# CONTROL_MODULE register map
Vendor: Texas Instruments
Registers are 32-bit, access per field, no defined reset value unless marked. A register's access mark holds for its fields unless they carry their own. Offsets are as the file gives them; [hi:lo] are bit positions.

## CONTROL_MODULE (part 3 of 5)
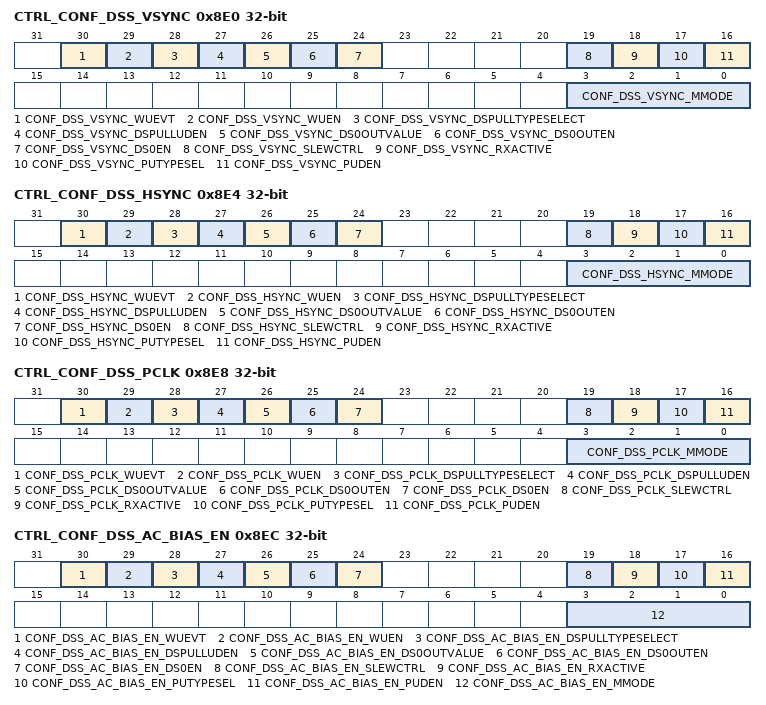
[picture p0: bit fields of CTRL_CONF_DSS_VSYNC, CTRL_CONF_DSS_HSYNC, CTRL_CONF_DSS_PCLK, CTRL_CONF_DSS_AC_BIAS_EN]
0x8E0 CTRL_CONF_DSS_VSYNC
  [30] CONF_DSS_VSYNC_WUEVT ro — Wakeup Event [[br]]0 = No event [[br]]1 = Event occurred
  [29] CONF_DSS_VSYNC_WUEN rw — Wakeup enable [[br]]0 = disable [[br]]1 = enable
  [28] CONF_DSS_VSYNC_DSPULLTYPESELECT rw — DS0 mode Pull-Up/Down selection [[br]]0 = Offmode Pull-Down selected [[br]]1 = Offmode Pull-Up selected
  [27] CONF_DSS_VSYNC_DSPULLUDEN rw — DS0 mode Pull-Up/Down enable. [[br]]This is an active low signal. [[br]]1 = Pullup / Pulldown disabled [[br]]0 = Pullup / Pulldown enabled
  [26] CONF_DSS_VSYNC_DS0OUTVALUE rw — DS0 mode output value [[br]]0 = Set value at 0 [[br]]1 = Set value at 1
  [25] CONF_DSS_VSYNC_DS0OUTEN rw — DS0 mode output enable This is an active low signal [[br]]0 = Output Enable [[br]]1 = Output Disable
  [24] CONF_DSS_VSYNC_DS0EN rw — DS0 mode override control [[br]]0: IO state keeps its previous state when DS0 mode is active [[br]]1: IO state is forced to OFF mode value when DS0 mode is active
  [19] CONF_DSS_VSYNC_SLEWCTRL rw — Select between Faster or Slower Slew rate [[br]]0 = fast [[br]]1 = slow
  [18] CONF_DSS_VSYNC_RXACTIVE rw — Input Enable Value for the PAD [[br]]0 = receiver disabled [[br]]1 = receiver enabled
  [17] CONF_DSS_VSYNC_PUTYPESEL rw — Pad Pullup / Pulldown Type Selection [[br]]0 = Pulldown selected [[br]]1 = Pullup selected
  [16] CONF_DSS_VSYNC_PUDEN rw — Pad Pullup / Pulldown Enable. [[br]]This is an active low signal [[br]]1 = Pullup / Pulldown disabled [[br]]0 = Pullup / Pulldown enabled
  [3:0] CONF_DSS_VSYNC_MMODE rw — Pad Functional Signal Mux Select
0x8E4 CTRL_CONF_DSS_HSYNC
  [30] CONF_DSS_HSYNC_WUEVT ro — Wakeup Event [[br]]0 = No event [[br]]1 = Event occurred
  [29] CONF_DSS_HSYNC_WUEN rw — Wakeup enable [[br]]0 = disable [[br]]1 = enable
  [28] CONF_DSS_HSYNC_DSPULLTYPESELECT rw — DS0 mode Pull-Up/Down selection [[br]]0 = Offmode Pull-Down selected [[br]]1 = Offmode Pull-Up selected
  [27] CONF_DSS_HSYNC_DSPULLUDEN rw — DS0 mode Pull-Up/Down enable. [[br]]This is an active low signal. [[br]]1 = Pullup / Pulldown disabled [[br]]0 = Pullup / Pulldown enabled
  [26] CONF_DSS_HSYNC_DS0OUTVALUE rw — DS0 mode output value [[br]]0 = Set value at 0 [[br]]1 = Set value at 1
  [25] CONF_DSS_HSYNC_DS0OUTEN rw — DS0 mode output enable This is an active low signal [[br]]0 = Output Enable [[br]]1 = Output Disable
  [24] CONF_DSS_HSYNC_DS0EN rw — DS0 mode override control [[br]]0: IO state keeps its previous state when DS0 mode is active [[br]]1: IO state is forced to OFF mode value when DS0 mode is active
  [19] CONF_DSS_HSYNC_SLEWCTRL rw — Select between Faster or Slower Slew rate [[br]]0 = fast [[br]]1 = slow
  [18] CONF_DSS_HSYNC_RXACTIVE rw — Input Enable Value for the PAD [[br]]0 = receiver disabled [[br]]1 = receiver enabled
  [17] CONF_DSS_HSYNC_PUTYPESEL rw — Pad Pullup / Pulldown Type Selection [[br]]0 = Pulldown selected [[br]]1 = Pullup selected
  [16] CONF_DSS_HSYNC_PUDEN rw — Pad Pullup / Pulldown Enable. [[br]]This is an active low signal [[br]]1 = Pullup / Pulldown disabled [[br]]0 = Pullup / Pulldown enabled
  [3:0] CONF_DSS_HSYNC_MMODE rw — Pad Functional Signal Mux Select
0x8E8 CTRL_CONF_DSS_PCLK
  [30] CONF_DSS_PCLK_WUEVT ro — Wakeup Event [[br]]0 = No event [[br]]1 = Event occurred
  [29] CONF_DSS_PCLK_WUEN rw — Wakeup enable [[br]]0 = disable [[br]]1 = enable
  [28] CONF_DSS_PCLK_DSPULLTYPESELECT rw — DS0 mode Pull-Up/Down selection [[br]]0 = Offmode Pull-Down selected [[br]]1 = Offmode Pull-Up selected
  [27] CONF_DSS_PCLK_DSPULLUDEN rw — DS0 mode Pull-Up/Down enable. [[br]]This is an active low signal. [[br]]1 = Pullup / Pulldown disabled [[br]]0 = Pullup / Pulldown enabled
  [26] CONF_DSS_PCLK_DS0OUTVALUE rw — DS0 mode output value [[br]]0 = Set value at 0 [[br]]1 = Set value at 1
  [25] CONF_DSS_PCLK_DS0OUTEN rw — DS0 mode output enable This is an active low signal [[br]]0 = Output Enable [[br]]1 = Output Disable
  [24] CONF_DSS_PCLK_DS0EN rw — DS0 mode override control [[br]]0: IO state keeps its previous state when DS0 mode is active [[br]]1: IO state is forced to OFF mode value when DS0 mode is active
  [19] CONF_DSS_PCLK_SLEWCTRL rw — Select between Faster or Slower Slew rate [[br]]0 = fast [[br]]1 = slow
  [18] CONF_DSS_PCLK_RXACTIVE rw — Input Enable Value for the PAD [[br]]0 = receiver disabled [[br]]1 = receiver enabled
  [17] CONF_DSS_PCLK_PUTYPESEL rw — Pad Pullup / Pulldown Type Selection [[br]]0 = Pulldown selected [[br]]1 = Pullup selected
  [16] CONF_DSS_PCLK_PUDEN rw — Pad Pullup / Pulldown Enable. [[br]]This is an active low signal [[br]]1 = Pullup / Pulldown disabled [[br]]0 = Pullup / Pulldown enabled
  [3:0] CONF_DSS_PCLK_MMODE rw — Pad Functional Signal Mux Select
0x8EC CTRL_CONF_DSS_AC_BIAS_EN
  [30] CONF_DSS_AC_BIAS_EN_WUEVT ro — Wakeup Event [[br]]0 = No event [[br]]1 = Event occurred
  [29] CONF_DSS_AC_BIAS_EN_WUEN rw — Wakeup enable [[br]]0 = disable [[br]]1 = enable
  [28] CONF_DSS_AC_BIAS_EN_DSPULLTYPESELECT rw — DS0 mode Pull-Up/Down selection [[br]]0 = Offmode Pull-Down selected [[br]]1 = Offmode Pull-Up selected
  [27] CONF_DSS_AC_BIAS_EN_DSPULLUDEN rw — DS0 mode Pull-Up/Down enable. [[br]]This is an active low signal. [[br]]1 = Pullup / Pulldown disabled [[br]]0 = Pullup / Pulldown enabled
  [26] CONF_DSS_AC_BIAS_EN_DS0OUTVALUE rw — DS0 mode output value [[br]]0 = Set value at 0 [[br]]1 = Set value at 1
  [25] CONF_DSS_AC_BIAS_EN_DS0OUTEN rw — DS0 mode output enable This is an active low signal [[br]]0 = Output Enable [[br]]1 = Output Disable
  [24] CONF_DSS_AC_BIAS_EN_DS0EN rw — DS0 mode override control [[br]]0: IO state keeps its previous state when DS0 mode is active [[br]]1: IO state is forced to OFF mode value when DS0 mode is active
  [19] CONF_DSS_AC_BIAS_EN_SLEWCTRL rw — Select between Faster or Slower Slew rate [[br]]0 = fast [[br]]1 = slow
  [18] CONF_DSS_AC_BIAS_EN_RXACTIVE rw — Input Enable Value for the PAD [[br]]0 = receiver disabled [[br]]1 = receiver enabled
  [17] CONF_DSS_AC_BIAS_EN_PUTYPESEL rw — Pad Pullup / Pulldown Type Selection [[br]]0 = Pulldown selected [[br]]1 = Pullup selected
  [16] CONF_DSS_AC_BIAS_EN_PUDEN rw — Pad Pullup / Pulldown Enable. [[br]]This is an active low signal [[br]]1 = Pullup / Pulldown disabled [[br]]0 = Pullup / Pulldown enabled
  [3:0] CONF_DSS_AC_BIAS_EN_MMODE rw — Pad Functional Signal Mux Select
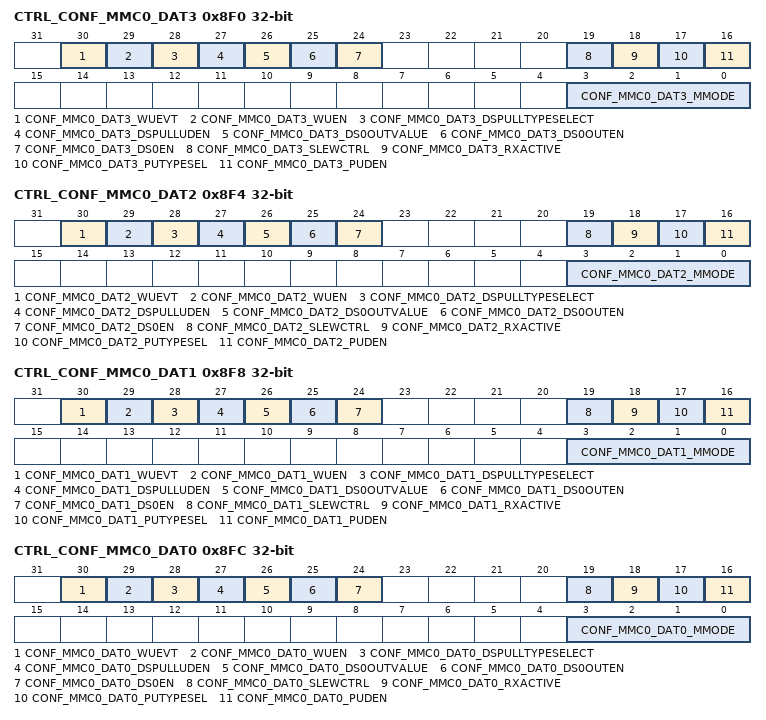
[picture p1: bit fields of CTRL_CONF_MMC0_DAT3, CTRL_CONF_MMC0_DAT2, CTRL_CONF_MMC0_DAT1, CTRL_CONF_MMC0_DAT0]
0x8F0 CTRL_CONF_MMC0_DAT3
  [30] CONF_MMC0_DAT3_WUEVT ro — Wakeup Event [[br]]0 = No event [[br]]1 = Event occurred
  [29] CONF_MMC0_DAT3_WUEN rw — Wakeup enable [[br]]0 = disable [[br]]1 = enable
  [28] CONF_MMC0_DAT3_DSPULLTYPESELECT rw — DS0 mode Pull-Up/Down selection [[br]]0 = Offmode Pull-Down selected [[br]]1 = Offmode Pull-Up selected
  [27] CONF_MMC0_DAT3_DSPULLUDEN rw — DS0 mode Pull-Up/Down enable. [[br]]This is an active low signal. [[br]]1 = Pullup / Pulldown disabled [[br]]0 = Pullup / Pulldown enabled
  [26] CONF_MMC0_DAT3_DS0OUTVALUE rw — DS0 mode output value [[br]]0 = Set value at 0 [[br]]1 = Set value at 1
  [25] CONF_MMC0_DAT3_DS0OUTEN rw — DS0 mode output enable This is an active low signal [[br]]0 = Output Enable [[br]]1 = Output Disable
  [24] CONF_MMC0_DAT3_DS0EN rw — DS0 mode override control [[br]]0: IO state keeps its previous state when DS0 mode is active [[br]]1: IO state is forced to OFF mode value when DS0 mode is active
  [19] CONF_MMC0_DAT3_SLEWCTRL rw — Select between Faster or Slower Slew rate [[br]]0 = fast [[br]]1 = slow
  [18] CONF_MMC0_DAT3_RXACTIVE rw — Input Enable Value for the PAD [[br]]0 = receiver disabled [[br]]1 = receiver enabled
  [17] CONF_MMC0_DAT3_PUTYPESEL rw — Pad Pullup / Pulldown Type Selection [[br]]0 = Pulldown selected [[br]]1 = Pullup selected
  [16] CONF_MMC0_DAT3_PUDEN rw — Pad Pullup / Pulldown Enable. [[br]]This is an active low signal [[br]]1 = Pullup / Pulldown disabled [[br]]0 = Pullup / Pulldown enabled
  [3:0] CONF_MMC0_DAT3_MMODE rw — Pad Functional Signal Mux Select
0x8F4 CTRL_CONF_MMC0_DAT2
  [30] CONF_MMC0_DAT2_WUEVT ro — Wakeup Event [[br]]0 = No event [[br]]1 = Event occurred
  [29] CONF_MMC0_DAT2_WUEN rw — Wakeup enable [[br]]0 = disable [[br]]1 = enable
  [28] CONF_MMC0_DAT2_DSPULLTYPESELECT rw — DS0 mode Pull-Up/Down selection [[br]]0 = Offmode Pull-Down selected [[br]]1 = Offmode Pull-Up selected
  [27] CONF_MMC0_DAT2_DSPULLUDEN rw — DS0 mode Pull-Up/Down enable. [[br]]This is an active low signal. [[br]]1 = Pullup / Pulldown disabled [[br]]0 = Pullup / Pulldown enabled
  [26] CONF_MMC0_DAT2_DS0OUTVALUE rw — DS0 mode output value [[br]]0 = Set value at 0 [[br]]1 = Set value at 1
  [25] CONF_MMC0_DAT2_DS0OUTEN rw — DS0 mode output enable This is an active low signal [[br]]0 = Output Enable [[br]]1 = Output Disable
  [24] CONF_MMC0_DAT2_DS0EN rw — DS0 mode override control [[br]]0: IO state keeps its previous state when DS0 mode is active [[br]]1: IO state is forced to OFF mode value when DS0 mode is active
  [19] CONF_MMC0_DAT2_SLEWCTRL rw — Select between Faster or Slower Slew rate [[br]]0 = fast [[br]]1 = slow
  [18] CONF_MMC0_DAT2_RXACTIVE rw — Input Enable Value for the PAD [[br]]0 = receiver disabled [[br]]1 = receiver enabled
  [17] CONF_MMC0_DAT2_PUTYPESEL rw — Pad Pullup / Pulldown Type Selection [[br]]0 = Pulldown selected [[br]]1 = Pullup selected
  [16] CONF_MMC0_DAT2_PUDEN rw — Pad Pullup / Pulldown Enable. [[br]]This is an active low signal [[br]]1 = Pullup / Pulldown disabled [[br]]0 = Pullup / Pulldown enabled
  [3:0] CONF_MMC0_DAT2_MMODE rw — Pad Functional Signal Mux Select
0x8F8 CTRL_CONF_MMC0_DAT1
  [30] CONF_MMC0_DAT1_WUEVT ro — Wakeup Event [[br]]0 = No event [[br]]1 = Event occurred
  [29] CONF_MMC0_DAT1_WUEN rw — Wakeup enable [[br]]0 = disable [[br]]1 = enable
  [28] CONF_MMC0_DAT1_DSPULLTYPESELECT rw — DS0 mode Pull-Up/Down selection [[br]]0 = Offmode Pull-Down selected [[br]]1 = Offmode Pull-Up selected
  [27] CONF_MMC0_DAT1_DSPULLUDEN rw — DS0 mode Pull-Up/Down enable. [[br]]This is an active low signal. [[br]]1 = Pullup / Pulldown disabled [[br]]0 = Pullup / Pulldown enabled
  [26] CONF_MMC0_DAT1_DS0OUTVALUE rw — DS0 mode output value [[br]]0 = Set value at 0 [[br]]1 = Set value at 1
  [25] CONF_MMC0_DAT1_DS0OUTEN rw — DS0 mode output enable This is an active low signal [[br]]0 = Output Enable [[br]]1 = Output Disable
  [24] CONF_MMC0_DAT1_DS0EN rw — DS0 mode override control [[br]]0: IO state keeps its previous state when DS0 mode is active [[br]]1: IO state is forced to OFF mode value when DS0 mode is active
  [19] CONF_MMC0_DAT1_SLEWCTRL rw — Select between Faster or Slower Slew rate [[br]]0 = fast [[br]]1 = slow
  [18] CONF_MMC0_DAT1_RXACTIVE rw — Input Enable Value for the PAD [[br]]0 = receiver disabled [[br]]1 = receiver enabled
  [17] CONF_MMC0_DAT1_PUTYPESEL rw — Pad Pullup / Pulldown Type Selection [[br]]0 = Pulldown selected [[br]]1 = Pullup selected
  [16] CONF_MMC0_DAT1_PUDEN rw — Pad Pullup / Pulldown Enable. [[br]]This is an active low signal [[br]]1 = Pullup / Pulldown disabled [[br]]0 = Pullup / Pulldown enabled
  [3:0] CONF_MMC0_DAT1_MMODE rw — Pad Functional Signal Mux Select
0x8FC CTRL_CONF_MMC0_DAT0
  [30] CONF_MMC0_DAT0_WUEVT ro — Wakeup Event [[br]]0 = No event [[br]]1 = Event occurred
  [29] CONF_MMC0_DAT0_WUEN rw — Wakeup enable [[br]]0 = disable [[br]]1 = enable
  [28] CONF_MMC0_DAT0_DSPULLTYPESELECT rw — DS0 mode Pull-Up/Down selection [[br]]0 = Offmode Pull-Down selected [[br]]1 = Offmode Pull-Up selected
  [27] CONF_MMC0_DAT0_DSPULLUDEN rw — DS0 mode Pull-Up/Down enable. [[br]]This is an active low signal. [[br]]1 = Pullup / Pulldown disabled [[br]]0 = Pullup / Pulldown enabled
  [26] CONF_MMC0_DAT0_DS0OUTVALUE rw — DS0 mode output value [[br]]0 = Set value at 0 [[br]]1 = Set value at 1
  [25] CONF_MMC0_DAT0_DS0OUTEN rw — DS0 mode output enable This is an active low signal [[br]]0 = Output Enable [[br]]1 = Output Disable
  [24] CONF_MMC0_DAT0_DS0EN rw — DS0 mode override control [[br]]0: IO state keeps its previous state when DS0 mode is active [[br]]1: IO state is forced to OFF mode value when DS0 mode is active
  [19] CONF_MMC0_DAT0_SLEWCTRL rw — Select between Faster or Slower Slew rate [[br]]0 = fast [[br]]1 = slow
  [18] CONF_MMC0_DAT0_RXACTIVE rw — Input Enable Value for the PAD [[br]]0 = receiver disabled [[br]]1 = receiver enabled
  [17] CONF_MMC0_DAT0_PUTYPESEL rw — Pad Pullup / Pulldown Type Selection [[br]]0 = Pulldown selected [[br]]1 = Pullup selected
  [16] CONF_MMC0_DAT0_PUDEN rw — Pad Pullup / Pulldown Enable. [[br]]This is an active low signal [[br]]1 = Pullup / Pulldown disabled [[br]]0 = Pullup / Pulldown enabled
  [3:0] CONF_MMC0_DAT0_MMODE rw — Pad Functional Signal Mux Select
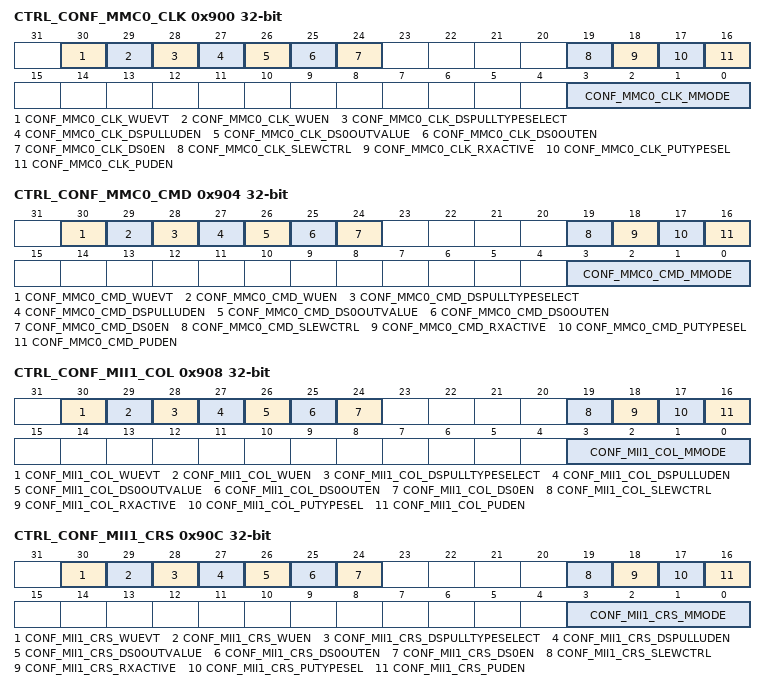
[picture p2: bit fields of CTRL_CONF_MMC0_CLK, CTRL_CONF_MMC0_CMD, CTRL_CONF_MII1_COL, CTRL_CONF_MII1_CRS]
0x900 CTRL_CONF_MMC0_CLK
  [30] CONF_MMC0_CLK_WUEVT ro — Wakeup Event [[br]]0 = No event [[br]]1 = Event occurred
  [29] CONF_MMC0_CLK_WUEN rw — Wakeup enable [[br]]0 = disable [[br]]1 = enable
  [28] CONF_MMC0_CLK_DSPULLTYPESELECT rw — DS0 mode Pull-Up/Down selection [[br]]0 = Offmode Pull-Down selected [[br]]1 = Offmode Pull-Up selected
  [27] CONF_MMC0_CLK_DSPULLUDEN rw — DS0 mode Pull-Up/Down enable. [[br]]This is an active low signal. [[br]]1 = Pullup / Pulldown disabled [[br]]0 = Pullup / Pulldown enabled
  [26] CONF_MMC0_CLK_DS0OUTVALUE rw — DS0 mode output value [[br]]0 = Set value at 0 [[br]]1 = Set value at 1
  [25] CONF_MMC0_CLK_DS0OUTEN rw — DS0 mode output enable This is an active low signal [[br]]0 = Output Enable [[br]]1 = Output Disable
  [24] CONF_MMC0_CLK_DS0EN rw — DS0 mode override control [[br]]0: IO state keeps its previous state when DS0 mode is active [[br]]1: IO state is forced to OFF mode value when DS0 mode is active
  [19] CONF_MMC0_CLK_SLEWCTRL rw — Select between Faster or Slower Slew rate [[br]]0 = fast [[br]]1 = slow
  [18] CONF_MMC0_CLK_RXACTIVE rw — Input Enable Value for the PAD [[br]]0 = receiver disabled [[br]]1 = receiver enabled
  [17] CONF_MMC0_CLK_PUTYPESEL rw — Pad Pullup / Pulldown Type Selection [[br]]0 = Pulldown selected [[br]]1 = Pullup selected
  [16] CONF_MMC0_CLK_PUDEN rw — Pad Pullup / Pulldown Enable. [[br]]This is an active low signal [[br]]1 = Pullup / Pulldown disabled [[br]]0 = Pullup / Pulldown enabled
  [3:0] CONF_MMC0_CLK_MMODE rw — Pad Functional Signal Mux Select
0x904 CTRL_CONF_MMC0_CMD
  [30] CONF_MMC0_CMD_WUEVT ro — Wakeup Event [[br]]0 = No event [[br]]1 = Event occurred
  [29] CONF_MMC0_CMD_WUEN rw — Wakeup enable [[br]]0 = disable [[br]]1 = enable
  [28] CONF_MMC0_CMD_DSPULLTYPESELECT rw — DS0 mode Pull-Up/Down selection [[br]]0 = Offmode Pull-Down selected [[br]]1 = Offmode Pull-Up selected
  [27] CONF_MMC0_CMD_DSPULLUDEN rw — DS0 mode Pull-Up/Down enable. [[br]]This is an active low signal. [[br]]1 = Pullup / Pulldown disabled [[br]]0 = Pullup / Pulldown enabled
  [26] CONF_MMC0_CMD_DS0OUTVALUE rw — DS0 mode output value [[br]]0 = Set value at 0 [[br]]1 = Set value at 1
  [25] CONF_MMC0_CMD_DS0OUTEN rw — DS0 mode output enable This is an active low signal [[br]]0 = Output Enable [[br]]1 = Output Disable
  [24] CONF_MMC0_CMD_DS0EN rw — DS0 mode override control [[br]]0: IO state keeps its previous state when DS0 mode is active [[br]]1: IO state is forced to OFF mode value when DS0 mode is active
  [19] CONF_MMC0_CMD_SLEWCTRL rw — Select between Faster or Slower Slew rate [[br]]0 = fast [[br]]1 = slow
  [18] CONF_MMC0_CMD_RXACTIVE rw — Input Enable Value for the PAD [[br]]0 = receiver disabled [[br]]1 = receiver enabled
  [17] CONF_MMC0_CMD_PUTYPESEL rw — Pad Pullup / Pulldown Type Selection [[br]]0 = Pulldown selected [[br]]1 = Pullup selected
  [16] CONF_MMC0_CMD_PUDEN rw — Pad Pullup / Pulldown Enable. [[br]]This is an active low signal [[br]]1 = Pullup / Pulldown disabled [[br]]0 = Pullup / Pulldown enabled
  [3:0] CONF_MMC0_CMD_MMODE rw — Pad Functional Signal Mux Select
0x908 CTRL_CONF_MII1_COL
  [30] CONF_MII1_COL_WUEVT ro — Wakeup Event [[br]]0 = No event [[br]]1 = Event occurred
  [29] CONF_MII1_COL_WUEN rw — Wakeup enable [[br]]0 = disable [[br]]1 = enable
  [28] CONF_MII1_COL_DSPULLTYPESELECT rw — DS0 mode Pull-Up/Down selection [[br]]0 = Offmode Pull-Down selected [[br]]1 = Offmode Pull-Up selected
  [27] CONF_MII1_COL_DSPULLUDEN rw — DS0 mode Pull-Up/Down enable. [[br]]This is an active low signal. [[br]]1 = Pullup / Pulldown disabled [[br]]0 = Pullup / Pulldown enabled
  [26] CONF_MII1_COL_DS0OUTVALUE rw — DS0 mode output value [[br]]0 = Set value at 0 [[br]]1 = Set value at 1
  [25] CONF_MII1_COL_DS0OUTEN rw — DS0 mode output enable This is an active low signal [[br]]0 = Output Enable [[br]]1 = Output Disable
  [24] CONF_MII1_COL_DS0EN rw — DS0 mode override control [[br]]0: IO state keeps its previous state when DS0 mode is active [[br]]1: IO state is forced to OFF mode value when DS0 mode is active
  [19] CONF_MII1_COL_SLEWCTRL rw — Select between Faster or Slower Slew rate [[br]]0 = fast [[br]]1 = slow
  [18] CONF_MII1_COL_RXACTIVE rw — Input Enable Value for the PAD [[br]]0 = receiver disabled [[br]]1 = receiver enabled
  [17] CONF_MII1_COL_PUTYPESEL rw — Pad Pullup / Pulldown Type Selection [[br]]0 = Pulldown selected [[br]]1 = Pullup selected
  [16] CONF_MII1_COL_PUDEN rw — Pad Pullup / Pulldown Enable. [[br]]This is an active low signal [[br]]1 = Pullup / Pulldown disabled [[br]]0 = Pullup / Pulldown enabled
  [3:0] CONF_MII1_COL_MMODE rw — Pad Functional Signal Mux Select
0x90C CTRL_CONF_MII1_CRS
  [30] CONF_MII1_CRS_WUEVT ro — Wakeup Event [[br]]0 = No event [[br]]1 = Event occurred
  [29] CONF_MII1_CRS_WUEN rw — Wakeup enable [[br]]0 = disable [[br]]1 = enable
  [28] CONF_MII1_CRS_DSPULLTYPESELECT rw — DS0 mode Pull-Up/Down selection [[br]]0 = Offmode Pull-Down selected [[br]]1 = Offmode Pull-Up selected
  [27] CONF_MII1_CRS_DSPULLUDEN rw — DS0 mode Pull-Up/Down enable. [[br]]This is an active low signal. [[br]]1 = Pullup / Pulldown disabled [[br]]0 = Pullup / Pulldown enabled
  [26] CONF_MII1_CRS_DS0OUTVALUE rw — DS0 mode output value [[br]]0 = Set value at 0 [[br]]1 = Set value at 1
  [25] CONF_MII1_CRS_DS0OUTEN rw — DS0 mode output enable This is an active low signal [[br]]0 = Output Enable [[br]]1 = Output Disable
  [24] CONF_MII1_CRS_DS0EN rw — DS0 mode override control [[br]]0: IO state keeps its previous state when DS0 mode is active [[br]]1: IO state is forced to OFF mode value when DS0 mode is active
  [19] CONF_MII1_CRS_SLEWCTRL rw — Select between Faster or Slower Slew rate [[br]]0 = fast [[br]]1 = slow
  [18] CONF_MII1_CRS_RXACTIVE rw — Input Enable Value for the PAD [[br]]0 = receiver disabled [[br]]1 = receiver enabled
  [17] CONF_MII1_CRS_PUTYPESEL rw — Pad Pullup / Pulldown Type Selection [[br]]0 = Pulldown selected [[br]]1 = Pullup selected
  [16] CONF_MII1_CRS_PUDEN rw — Pad Pullup / Pulldown Enable. [[br]]This is an active low signal [[br]]1 = Pullup / Pulldown disabled [[br]]0 = Pullup / Pulldown enabled
  [3:0] CONF_MII1_CRS_MMODE rw — Pad Functional Signal Mux Select
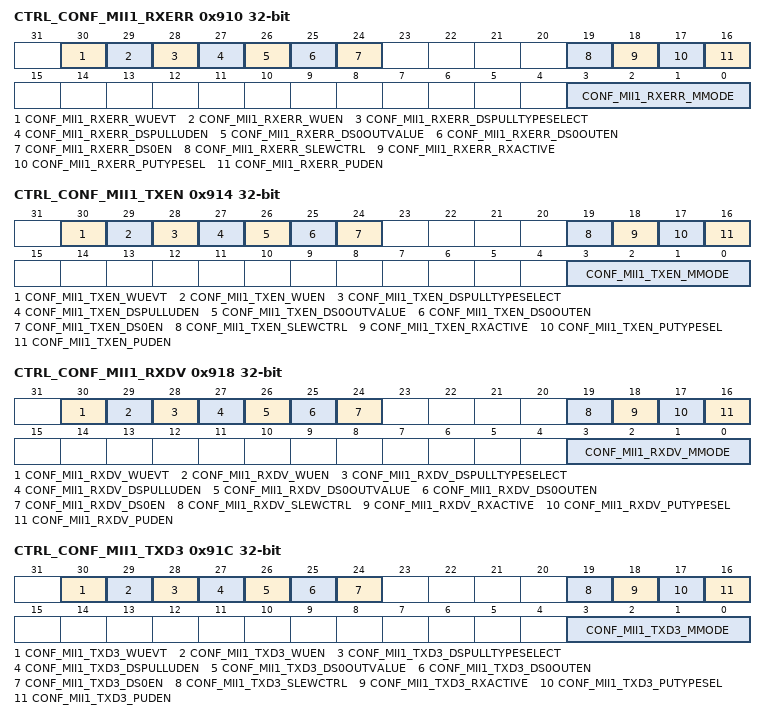
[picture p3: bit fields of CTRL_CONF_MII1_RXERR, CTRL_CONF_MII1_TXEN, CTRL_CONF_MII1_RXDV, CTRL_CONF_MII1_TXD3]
0x910 CTRL_CONF_MII1_RXERR
  [30] CONF_MII1_RXERR_WUEVT ro — Wakeup Event [[br]]0 = No event [[br]]1 = Event occurred
  [29] CONF_MII1_RXERR_WUEN rw — Wakeup enable [[br]]0 = disable [[br]]1 = enable
  [28] CONF_MII1_RXERR_DSPULLTYPESELECT rw — DS0 mode Pull-Up/Down selection [[br]]0 = Offmode Pull-Down selected [[br]]1 = Offmode Pull-Up selected
  [27] CONF_MII1_RXERR_DSPULLUDEN rw — DS0 mode Pull-Up/Down enable. [[br]]This is an active low signal. [[br]]1 = Pullup / Pulldown disabled [[br]]0 = Pullup / Pulldown enabled
  [26] CONF_MII1_RXERR_DS0OUTVALUE rw — DS0 mode output value [[br]]0 = Set value at 0 [[br]]1 = Set value at 1
  [25] CONF_MII1_RXERR_DS0OUTEN rw — DS0 mode output enable This is an active low signal [[br]]0 = Output Enable [[br]]1 = Output Disable
  [24] CONF_MII1_RXERR_DS0EN rw — DS0 mode override control [[br]]0: IO state keeps its previous state when DS0 mode is active [[br]]1: IO state is forced to OFF mode value when DS0 mode is active
  [19] CONF_MII1_RXERR_SLEWCTRL rw — Select between Faster or Slower Slew rate [[br]]0 = fast [[br]]1 = slow
  [18] CONF_MII1_RXERR_RXACTIVE rw — Input Enable Value for the PAD [[br]]0 = receiver disabled [[br]]1 = receiver enabled
  [17] CONF_MII1_RXERR_PUTYPESEL rw — Pad Pullup / Pulldown Type Selection [[br]]0 = Pulldown selected [[br]]1 = Pullup selected
  [16] CONF_MII1_RXERR_PUDEN rw — Pad Pullup / Pulldown Enable. [[br]]This is an active low signal [[br]]1 = Pullup / Pulldown disabled [[br]]0 = Pullup / Pulldown enabled
  [3:0] CONF_MII1_RXERR_MMODE rw — Pad Functional Signal Mux Select
0x914 CTRL_CONF_MII1_TXEN
  [30] CONF_MII1_TXEN_WUEVT ro — Wakeup Event [[br]]0 = No event [[br]]1 = Event occurred
  [29] CONF_MII1_TXEN_WUEN rw — Wakeup enable [[br]]0 = disable [[br]]1 = enable
  [28] CONF_MII1_TXEN_DSPULLTYPESELECT rw — DS0 mode Pull-Up/Down selection [[br]]0 = Offmode Pull-Down selected [[br]]1 = Offmode Pull-Up selected
  [27] CONF_MII1_TXEN_DSPULLUDEN rw — DS0 mode Pull-Up/Down enable. [[br]]This is an active low signal. [[br]]1 = Pullup / Pulldown disabled [[br]]0 = Pullup / Pulldown enabled
  [26] CONF_MII1_TXEN_DS0OUTVALUE rw — DS0 mode output value [[br]]0 = Set value at 0 [[br]]1 = Set value at 1
  [25] CONF_MII1_TXEN_DS0OUTEN rw — DS0 mode output enable This is an active low signal [[br]]0 = Output Enable [[br]]1 = Output Disable
  [24] CONF_MII1_TXEN_DS0EN rw — DS0 mode override control [[br]]0: IO state keeps its previous state when DS0 mode is active [[br]]1: IO state is forced to OFF mode value when DS0 mode is active
  [19] CONF_MII1_TXEN_SLEWCTRL rw — Select between Faster or Slower Slew rate [[br]]0 = fast [[br]]1 = slow
  [18] CONF_MII1_TXEN_RXACTIVE rw — Input Enable Value for the PAD [[br]]0 = receiver disabled [[br]]1 = receiver enabled
  [17] CONF_MII1_TXEN_PUTYPESEL rw — Pad Pullup / Pulldown Type Selection [[br]]0 = Pulldown selected [[br]]1 = Pullup selected
  [16] CONF_MII1_TXEN_PUDEN rw — Pad Pullup / Pulldown Enable. [[br]]This is an active low signal [[br]]1 = Pullup / Pulldown disabled [[br]]0 = Pullup / Pulldown enabled
  [3:0] CONF_MII1_TXEN_MMODE rw — Pad Functional Signal Mux Select
0x918 CTRL_CONF_MII1_RXDV
  [30] CONF_MII1_RXDV_WUEVT ro — Wakeup Event [[br]]0 = No event [[br]]1 = Event occurred
  [29] CONF_MII1_RXDV_WUEN rw — Wakeup enable [[br]]0 = disable [[br]]1 = enable
  [28] CONF_MII1_RXDV_DSPULLTYPESELECT rw — DS0 mode Pull-Up/Down selection [[br]]0 = Offmode Pull-Down selected [[br]]1 = Offmode Pull-Up selected
  [27] CONF_MII1_RXDV_DSPULLUDEN rw — DS0 mode Pull-Up/Down enable. [[br]]This is an active low signal. [[br]]1 = Pullup / Pulldown disabled [[br]]0 = Pullup / Pulldown enabled
  [26] CONF_MII1_RXDV_DS0OUTVALUE rw — DS0 mode output value [[br]]0 = Set value at 0 [[br]]1 = Set value at 1
  [25] CONF_MII1_RXDV_DS0OUTEN rw — DS0 mode output enable This is an active low signal [[br]]0 = Output Enable [[br]]1 = Output Disable
  [24] CONF_MII1_RXDV_DS0EN rw — DS0 mode override control [[br]]0: IO state keeps its previous state when DS0 mode is active [[br]]1: IO state is forced to OFF mode value when DS0 mode is active
  [19] CONF_MII1_RXDV_SLEWCTRL rw — Select between Faster or Slower Slew rate [[br]]0 = fast [[br]]1 = slow
  [18] CONF_MII1_RXDV_RXACTIVE rw — Input Enable Value for the PAD [[br]]0 = receiver disabled [[br]]1 = receiver enabled
  [17] CONF_MII1_RXDV_PUTYPESEL rw — Pad Pullup / Pulldown Type Selection [[br]]0 = Pulldown selected [[br]]1 = Pullup selected
  [16] CONF_MII1_RXDV_PUDEN rw — Pad Pullup / Pulldown Enable. [[br]]This is an active low signal [[br]]1 = Pullup / Pulldown disabled [[br]]0 = Pullup / Pulldown enabled
  [3:0] CONF_MII1_RXDV_MMODE rw — Pad Functional Signal Mux Select
0x91C CTRL_CONF_MII1_TXD3
  [30] CONF_MII1_TXD3_WUEVT ro — Wakeup Event [[br]]0 = No event [[br]]1 = Event occurred
  [29] CONF_MII1_TXD3_WUEN rw — Wakeup enable [[br]]0 = disable [[br]]1 = enable
  [28] CONF_MII1_TXD3_DSPULLTYPESELECT rw — DS0 mode Pull-Up/Down selection [[br]]0 = Offmode Pull-Down selected [[br]]1 = Offmode Pull-Up selected
  [27] CONF_MII1_TXD3_DSPULLUDEN rw — DS0 mode Pull-Up/Down enable. [[br]]This is an active low signal. [[br]]1 = Pullup / Pulldown disabled [[br]]0 = Pullup / Pulldown enabled
  [26] CONF_MII1_TXD3_DS0OUTVALUE rw — DS0 mode output value [[br]]0 = Set value at 0 [[br]]1 = Set value at 1
  [25] CONF_MII1_TXD3_DS0OUTEN rw — DS0 mode output enable This is an active low signal [[br]]0 = Output Enable [[br]]1 = Output Disable
  [24] CONF_MII1_TXD3_DS0EN rw — DS0 mode override control [[br]]0: IO state keeps its previous state when DS0 mode is active [[br]]1: IO state is forced to OFF mode value when DS0 mode is active
  [19] CONF_MII1_TXD3_SLEWCTRL rw — Select between Faster or Slower Slew rate [[br]]0 = fast [[br]]1 = slow
  [18] CONF_MII1_TXD3_RXACTIVE rw — Input Enable Value for the PAD [[br]]0 = receiver disabled [[br]]1 = receiver enabled
  [17] CONF_MII1_TXD3_PUTYPESEL rw — Pad Pullup / Pulldown Type Selection [[br]]0 = Pulldown selected [[br]]1 = Pullup selected
  [16] CONF_MII1_TXD3_PUDEN rw — Pad Pullup / Pulldown Enable. [[br]]This is an active low signal [[br]]1 = Pullup / Pulldown disabled [[br]]0 = Pullup / Pulldown enabled
  [3:0] CONF_MII1_TXD3_MMODE rw — Pad Functional Signal Mux Select
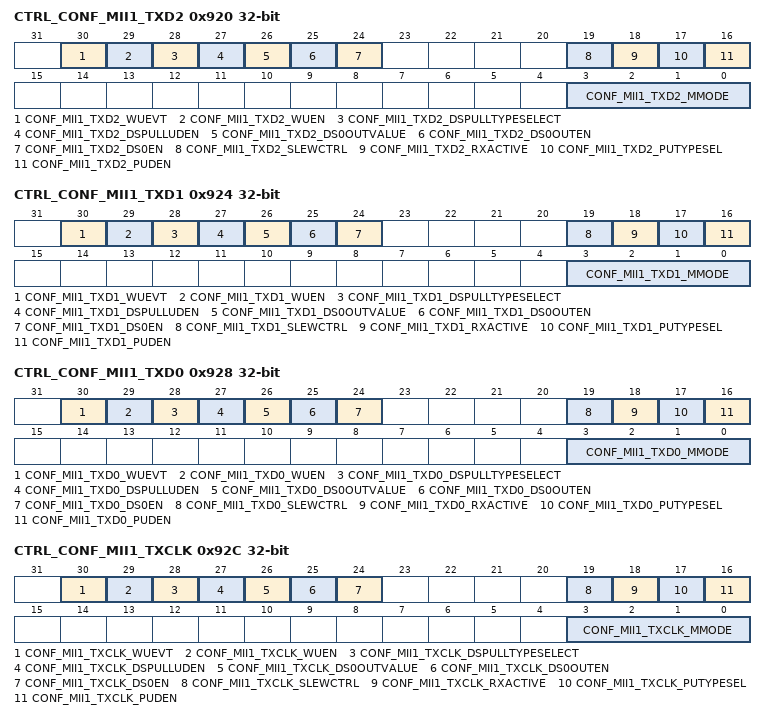
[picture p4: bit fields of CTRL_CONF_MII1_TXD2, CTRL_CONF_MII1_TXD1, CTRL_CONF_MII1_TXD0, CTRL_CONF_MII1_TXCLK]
0x920 CTRL_CONF_MII1_TXD2
  [30] CONF_MII1_TXD2_WUEVT ro — Wakeup Event [[br]]0 = No event [[br]]1 = Event occurred
  [29] CONF_MII1_TXD2_WUEN rw — Wakeup enable [[br]]0 = disable [[br]]1 = enable
  [28] CONF_MII1_TXD2_DSPULLTYPESELECT rw — DS0 mode Pull-Up/Down selection [[br]]0 = Offmode Pull-Down selected [[br]]1 = Offmode Pull-Up selected
  [27] CONF_MII1_TXD2_DSPULLUDEN rw — DS0 mode Pull-Up/Down enable. [[br]]This is an active low signal. [[br]]1 = Pullup / Pulldown disabled [[br]]0 = Pullup / Pulldown enabled
  [26] CONF_MII1_TXD2_DS0OUTVALUE rw — DS0 mode output value [[br]]0 = Set value at 0 [[br]]1 = Set value at 1
  [25] CONF_MII1_TXD2_DS0OUTEN rw — DS0 mode output enable This is an active low signal [[br]]0 = Output Enable [[br]]1 = Output Disable
  [24] CONF_MII1_TXD2_DS0EN rw — DS0 mode override control [[br]]0: IO state keeps its previous state when DS0 mode is active [[br]]1: IO state is forced to OFF mode value when DS0 mode is active
  [19] CONF_MII1_TXD2_SLEWCTRL rw — Select between Faster or Slower Slew rate [[br]]0 = fast [[br]]1 = slow
  [18] CONF_MII1_TXD2_RXACTIVE rw — Input Enable Value for the PAD [[br]]0 = receiver disabled [[br]]1 = receiver enabled
  [17] CONF_MII1_TXD2_PUTYPESEL rw — Pad Pullup / Pulldown Type Selection [[br]]0 = Pulldown selected [[br]]1 = Pullup selected
  [16] CONF_MII1_TXD2_PUDEN rw — Pad Pullup / Pulldown Enable. [[br]]This is an active low signal [[br]]1 = Pullup / Pulldown disabled [[br]]0 = Pullup / Pulldown enabled
  [3:0] CONF_MII1_TXD2_MMODE rw — Pad Functional Signal Mux Select
0x924 CTRL_CONF_MII1_TXD1
  [30] CONF_MII1_TXD1_WUEVT ro — Wakeup Event [[br]]0 = No event [[br]]1 = Event occurred
  [29] CONF_MII1_TXD1_WUEN rw — Wakeup enable [[br]]0 = disable [[br]]1 = enable
  [28] CONF_MII1_TXD1_DSPULLTYPESELECT rw — DS0 mode Pull-Up/Down selection [[br]]0 = Offmode Pull-Down selected [[br]]1 = Offmode Pull-Up selected
  [27] CONF_MII1_TXD1_DSPULLUDEN rw — DS0 mode Pull-Up/Down enable. [[br]]This is an active low signal. [[br]]1 = Pullup / Pulldown disabled [[br]]0 = Pullup / Pulldown enabled
  [26] CONF_MII1_TXD1_DS0OUTVALUE rw — DS0 mode output value [[br]]0 = Set value at 0 [[br]]1 = Set value at 1
  [25] CONF_MII1_TXD1_DS0OUTEN rw — DS0 mode output enable This is an active low signal [[br]]0 = Output Enable [[br]]1 = Output Disable
  [24] CONF_MII1_TXD1_DS0EN rw — DS0 mode override control [[br]]0: IO state keeps its previous state when DS0 mode is active [[br]]1: IO state is forced to OFF mode value when DS0 mode is active
  [19] CONF_MII1_TXD1_SLEWCTRL rw — Select between Faster or Slower Slew rate [[br]]0 = fast [[br]]1 = slow
  [18] CONF_MII1_TXD1_RXACTIVE rw — Input Enable Value for the PAD [[br]]0 = receiver disabled [[br]]1 = receiver enabled
  [17] CONF_MII1_TXD1_PUTYPESEL rw — Pad Pullup / Pulldown Type Selection [[br]]0 = Pulldown selected [[br]]1 = Pullup selected
  [16] CONF_MII1_TXD1_PUDEN rw — Pad Pullup / Pulldown Enable. [[br]]This is an active low signal [[br]]1 = Pullup / Pulldown disabled [[br]]0 = Pullup / Pulldown enabled
  [3:0] CONF_MII1_TXD1_MMODE rw — Pad Functional Signal Mux Select
0x928 CTRL_CONF_MII1_TXD0
  [30] CONF_MII1_TXD0_WUEVT ro — Wakeup Event [[br]]0 = No event [[br]]1 = Event occurred
  [29] CONF_MII1_TXD0_WUEN rw — Wakeup enable [[br]]0 = disable [[br]]1 = enable
  [28] CONF_MII1_TXD0_DSPULLTYPESELECT rw — DS0 mode Pull-Up/Down selection [[br]]0 = Offmode Pull-Down selected [[br]]1 = Offmode Pull-Up selected
  [27] CONF_MII1_TXD0_DSPULLUDEN rw — DS0 mode Pull-Up/Down enable. [[br]]This is an active low signal. [[br]]1 = Pullup / Pulldown disabled [[br]]0 = Pullup / Pulldown enabled
  [26] CONF_MII1_TXD0_DS0OUTVALUE rw — DS0 mode output value [[br]]0 = Set value at 0 [[br]]1 = Set value at 1
  [25] CONF_MII1_TXD0_DS0OUTEN rw — DS0 mode output enable This is an active low signal [[br]]0 = Output Enable [[br]]1 = Output Disable
  [24] CONF_MII1_TXD0_DS0EN rw — DS0 mode override control [[br]]0: IO state keeps its previous state when DS0 mode is active [[br]]1: IO state is forced to OFF mode value when DS0 mode is active
  [19] CONF_MII1_TXD0_SLEWCTRL rw — Select between Faster or Slower Slew rate [[br]]0 = fast [[br]]1 = slow
  [18] CONF_MII1_TXD0_RXACTIVE rw — Input Enable Value for the PAD [[br]]0 = receiver disabled [[br]]1 = receiver enabled
  [17] CONF_MII1_TXD0_PUTYPESEL rw — Pad Pullup / Pulldown Type Selection [[br]]0 = Pulldown selected [[br]]1 = Pullup selected
  [16] CONF_MII1_TXD0_PUDEN rw — Pad Pullup / Pulldown Enable. [[br]]This is an active low signal [[br]]1 = Pullup / Pulldown disabled [[br]]0 = Pullup / Pulldown enabled
  [3:0] CONF_MII1_TXD0_MMODE rw — Pad Functional Signal Mux Select
0x92C CTRL_CONF_MII1_TXCLK
  [30] CONF_MII1_TXCLK_WUEVT ro — Wakeup Event [[br]]0 = No event [[br]]1 = Event occurred
  [29] CONF_MII1_TXCLK_WUEN rw — Wakeup enable [[br]]0 = disable [[br]]1 = enable
  [28] CONF_MII1_TXCLK_DSPULLTYPESELECT rw — DS0 mode Pull-Up/Down selection [[br]]0 = Offmode Pull-Down selected [[br]]1 = Offmode Pull-Up selected
  [27] CONF_MII1_TXCLK_DSPULLUDEN rw — DS0 mode Pull-Up/Down enable. [[br]]This is an active low signal. [[br]]1 = Pullup / Pulldown disabled [[br]]0 = Pullup / Pulldown enabled
  [26] CONF_MII1_TXCLK_DS0OUTVALUE rw — DS0 mode output value [[br]]0 = Set value at 0 [[br]]1 = Set value at 1
  [25] CONF_MII1_TXCLK_DS0OUTEN rw — DS0 mode output enable This is an active low signal [[br]]0 = Output Enable [[br]]1 = Output Disable
  [24] CONF_MII1_TXCLK_DS0EN rw — DS0 mode override control [[br]]0: IO state keeps its previous state when DS0 mode is active [[br]]1: IO state is forced to OFF mode value when DS0 mode is active
  [19] CONF_MII1_TXCLK_SLEWCTRL rw — Select between Faster or Slower Slew rate [[br]]0 = fast [[br]]1 = slow
  [18] CONF_MII1_TXCLK_RXACTIVE rw — Input Enable Value for the PAD [[br]]0 = receiver disabled [[br]]1 = receiver enabled
  [17] CONF_MII1_TXCLK_PUTYPESEL rw — Pad Pullup / Pulldown Type Selection [[br]]0 = Pulldown selected [[br]]1 = Pullup selected
  [16] CONF_MII1_TXCLK_PUDEN rw — Pad Pullup / Pulldown Enable. [[br]]This is an active low signal [[br]]1 = Pullup / Pulldown disabled [[br]]0 = Pullup / Pulldown enabled
  [3:0] CONF_MII1_TXCLK_MMODE rw — Pad Functional Signal Mux Select
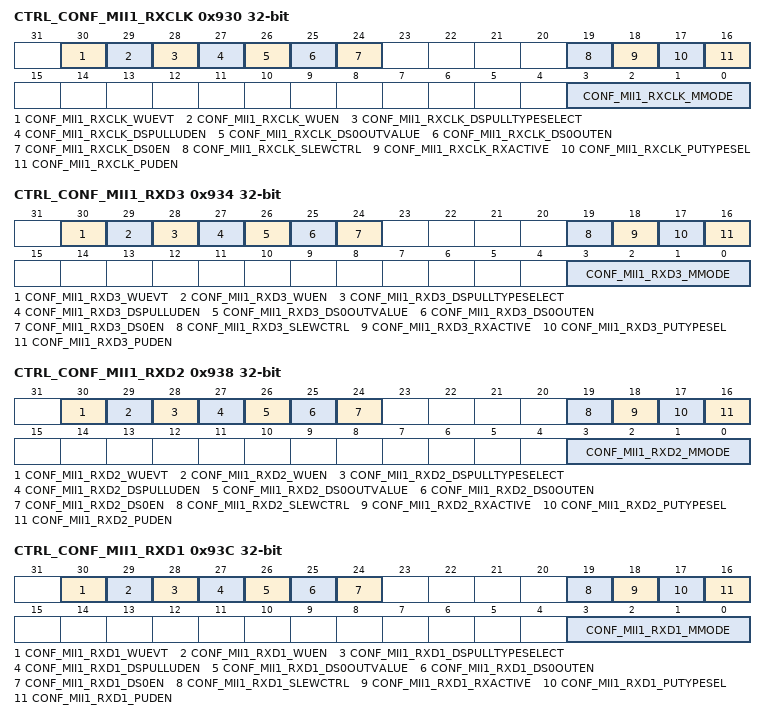
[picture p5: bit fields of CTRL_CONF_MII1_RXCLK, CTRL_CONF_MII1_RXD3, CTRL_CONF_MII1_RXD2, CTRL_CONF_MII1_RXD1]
0x930 CTRL_CONF_MII1_RXCLK
  [30] CONF_MII1_RXCLK_WUEVT ro — Wakeup Event [[br]]0 = No event [[br]]1 = Event occurred
  [29] CONF_MII1_RXCLK_WUEN rw — Wakeup enable [[br]]0 = disable [[br]]1 = enable
  [28] CONF_MII1_RXCLK_DSPULLTYPESELECT rw — DS0 mode Pull-Up/Down selection [[br]]0 = Offmode Pull-Down selected [[br]]1 = Offmode Pull-Up selected
  [27] CONF_MII1_RXCLK_DSPULLUDEN rw — DS0 mode Pull-Up/Down enable. [[br]]This is an active low signal. [[br]]1 = Pullup / Pulldown disabled [[br]]0 = Pullup / Pulldown enabled
  [26] CONF_MII1_RXCLK_DS0OUTVALUE rw — DS0 mode output value [[br]]0 = Set value at 0 [[br]]1 = Set value at 1
  [25] CONF_MII1_RXCLK_DS0OUTEN rw — DS0 mode output enable This is an active low signal [[br]]0 = Output Enable [[br]]1 = Output Disable
  [24] CONF_MII1_RXCLK_DS0EN rw — DS0 mode override control [[br]]0: IO state keeps its previous state when DS0 mode is active [[br]]1: IO state is forced to OFF mode value when DS0 mode is active
  [19] CONF_MII1_RXCLK_SLEWCTRL rw — Select between Faster or Slower Slew rate [[br]]0 = fast [[br]]1 = slow
  [18] CONF_MII1_RXCLK_RXACTIVE rw — Input Enable Value for the PAD [[br]]0 = receiver disabled [[br]]1 = receiver enabled
  [17] CONF_MII1_RXCLK_PUTYPESEL rw — Pad Pullup / Pulldown Type Selection [[br]]0 = Pulldown selected [[br]]1 = Pullup selected
  [16] CONF_MII1_RXCLK_PUDEN rw — Pad Pullup / Pulldown Enable. [[br]]This is an active low signal [[br]]1 = Pullup / Pulldown disabled [[br]]0 = Pullup / Pulldown enabled
  [3:0] CONF_MII1_RXCLK_MMODE rw — Pad Functional Signal Mux Select
0x934 CTRL_CONF_MII1_RXD3
  [30] CONF_MII1_RXD3_WUEVT ro — Wakeup Event [[br]]0 = No event [[br]]1 = Event occurred
  [29] CONF_MII1_RXD3_WUEN rw — Wakeup enable [[br]]0 = disable [[br]]1 = enable
  [28] CONF_MII1_RXD3_DSPULLTYPESELECT rw — DS0 mode Pull-Up/Down selection [[br]]0 = Offmode Pull-Down selected [[br]]1 = Offmode Pull-Up selected
  [27] CONF_MII1_RXD3_DSPULLUDEN rw — DS0 mode Pull-Up/Down enable. [[br]]This is an active low signal. [[br]]1 = Pullup / Pulldown disabled [[br]]0 = Pullup / Pulldown enabled
  [26] CONF_MII1_RXD3_DS0OUTVALUE rw — DS0 mode output value [[br]]0 = Set value at 0 [[br]]1 = Set value at 1
  [25] CONF_MII1_RXD3_DS0OUTEN rw — DS0 mode output enable This is an active low signal [[br]]0 = Output Enable [[br]]1 = Output Disable
  [24] CONF_MII1_RXD3_DS0EN rw — DS0 mode override control [[br]]0: IO state keeps its previous state when DS0 mode is active [[br]]1: IO state is forced to OFF mode value when DS0 mode is active
  [19] CONF_MII1_RXD3_SLEWCTRL rw — Select between Faster or Slower Slew rate [[br]]0 = fast [[br]]1 = slow
  [18] CONF_MII1_RXD3_RXACTIVE rw — Input Enable Value for the PAD [[br]]0 = receiver disabled [[br]]1 = receiver enabled
  [17] CONF_MII1_RXD3_PUTYPESEL rw — Pad Pullup / Pulldown Type Selection [[br]]0 = Pulldown selected [[br]]1 = Pullup selected
  [16] CONF_MII1_RXD3_PUDEN rw — Pad Pullup / Pulldown Enable. [[br]]This is an active low signal [[br]]1 = Pullup / Pulldown disabled [[br]]0 = Pullup / Pulldown enabled
  [3:0] CONF_MII1_RXD3_MMODE rw — Pad Functional Signal Mux Select
0x938 CTRL_CONF_MII1_RXD2
  [30] CONF_MII1_RXD2_WUEVT ro — Wakeup Event [[br]]0 = No event [[br]]1 = Event occurred
  [29] CONF_MII1_RXD2_WUEN rw — Wakeup enable [[br]]0 = disable [[br]]1 = enable
  [28] CONF_MII1_RXD2_DSPULLTYPESELECT rw — DS0 mode Pull-Up/Down selection [[br]]0 = Offmode Pull-Down selected [[br]]1 = Offmode Pull-Up selected
  [27] CONF_MII1_RXD2_DSPULLUDEN rw — DS0 mode Pull-Up/Down enable. [[br]]This is an active low signal. [[br]]1 = Pullup / Pulldown disabled [[br]]0 = Pullup / Pulldown enabled
  [26] CONF_MII1_RXD2_DS0OUTVALUE rw — DS0 mode output value [[br]]0 = Set value at 0 [[br]]1 = Set value at 1
  [25] CONF_MII1_RXD2_DS0OUTEN rw — DS0 mode output enable This is an active low signal [[br]]0 = Output Enable [[br]]1 = Output Disable
  [24] CONF_MII1_RXD2_DS0EN rw — DS0 mode override control [[br]]0: IO state keeps its previous state when DS0 mode is active [[br]]1: IO state is forced to OFF mode value when DS0 mode is active
  [19] CONF_MII1_RXD2_SLEWCTRL rw — Select between Faster or Slower Slew rate [[br]]0 = fast [[br]]1 = slow
  [18] CONF_MII1_RXD2_RXACTIVE rw — Input Enable Value for the PAD [[br]]0 = receiver disabled [[br]]1 = receiver enabled
  [17] CONF_MII1_RXD2_PUTYPESEL rw — Pad Pullup / Pulldown Type Selection [[br]]0 = Pulldown selected [[br]]1 = Pullup selected
  [16] CONF_MII1_RXD2_PUDEN rw — Pad Pullup / Pulldown Enable. [[br]]This is an active low signal [[br]]1 = Pullup / Pulldown disabled [[br]]0 = Pullup / Pulldown enabled
  [3:0] CONF_MII1_RXD2_MMODE rw — Pad Functional Signal Mux Select
0x93C CTRL_CONF_MII1_RXD1
  [30] CONF_MII1_RXD1_WUEVT ro — Wakeup Event [[br]]0 = No event [[br]]1 = Event occurred
  [29] CONF_MII1_RXD1_WUEN rw — Wakeup enable [[br]]0 = disable [[br]]1 = enable
  [28] CONF_MII1_RXD1_DSPULLTYPESELECT rw — DS0 mode Pull-Up/Down selection [[br]]0 = Offmode Pull-Down selected [[br]]1 = Offmode Pull-Up selected
  [27] CONF_MII1_RXD1_DSPULLUDEN rw — DS0 mode Pull-Up/Down enable. [[br]]This is an active low signal. [[br]]1 = Pullup / Pulldown disabled [[br]]0 = Pullup / Pulldown enabled
  [26] CONF_MII1_RXD1_DS0OUTVALUE rw — DS0 mode output value [[br]]0 = Set value at 0 [[br]]1 = Set value at 1
  [25] CONF_MII1_RXD1_DS0OUTEN rw — DS0 mode output enable This is an active low signal [[br]]0 = Output Enable [[br]]1 = Output Disable
  [24] CONF_MII1_RXD1_DS0EN rw — DS0 mode override control [[br]]0: IO state keeps its previous state when DS0 mode is active [[br]]1: IO state is forced to OFF mode value when DS0 mode is active
  [19] CONF_MII1_RXD1_SLEWCTRL rw — Select between Faster or Slower Slew rate [[br]]0 = fast [[br]]1 = slow
  [18] CONF_MII1_RXD1_RXACTIVE rw — Input Enable Value for the PAD [[br]]0 = receiver disabled [[br]]1 = receiver enabled
  [17] CONF_MII1_RXD1_PUTYPESEL rw — Pad Pullup / Pulldown Type Selection [[br]]0 = Pulldown selected [[br]]1 = Pullup selected
  [16] CONF_MII1_RXD1_PUDEN rw — Pad Pullup / Pulldown Enable. [[br]]This is an active low signal [[br]]1 = Pullup / Pulldown disabled [[br]]0 = Pullup / Pulldown enabled
  [3:0] CONF_MII1_RXD1_MMODE rw — Pad Functional Signal Mux Select
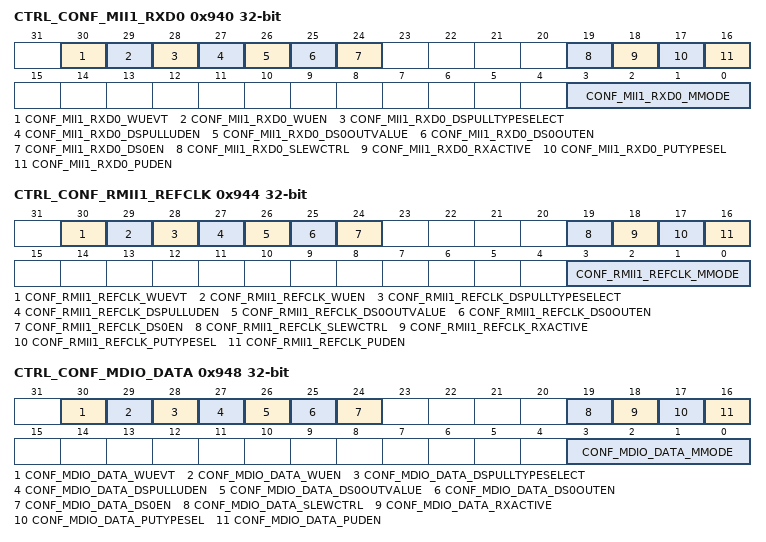
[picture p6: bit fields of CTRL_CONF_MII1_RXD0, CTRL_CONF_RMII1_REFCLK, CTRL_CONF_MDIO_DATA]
0x940 CTRL_CONF_MII1_RXD0
  [30] CONF_MII1_RXD0_WUEVT ro — Wakeup Event [[br]]0 = No event [[br]]1 = Event occurred
  [29] CONF_MII1_RXD0_WUEN rw — Wakeup enable [[br]]0 = disable [[br]]1 = enable
  [28] CONF_MII1_RXD0_DSPULLTYPESELECT rw — DS0 mode Pull-Up/Down selection [[br]]0 = Offmode Pull-Down selected [[br]]1 = Offmode Pull-Up selected
  [27] CONF_MII1_RXD0_DSPULLUDEN rw — DS0 mode Pull-Up/Down enable. [[br]]This is an active low signal. [[br]]1 = Pullup / Pulldown disabled [[br]]0 = Pullup / Pulldown enabled
  [26] CONF_MII1_RXD0_DS0OUTVALUE rw — DS0 mode output value [[br]]0 = Set value at 0 [[br]]1 = Set value at 1
  [25] CONF_MII1_RXD0_DS0OUTEN rw — DS0 mode output enable This is an active low signal [[br]]0 = Output Enable [[br]]1 = Output Disable
  [24] CONF_MII1_RXD0_DS0EN rw — DS0 mode override control [[br]]0: IO state keeps its previous state when DS0 mode is active [[br]]1: IO state is forced to OFF mode value when DS0 mode is active
  [19] CONF_MII1_RXD0_SLEWCTRL rw — Select between Faster or Slower Slew rate [[br]]0 = fast [[br]]1 = slow
  [18] CONF_MII1_RXD0_RXACTIVE rw — Input Enable Value for the PAD [[br]]0 = receiver disabled [[br]]1 = receiver enabled
  [17] CONF_MII1_RXD0_PUTYPESEL rw — Pad Pullup / Pulldown Type Selection [[br]]0 = Pulldown selected [[br]]1 = Pullup selected
  [16] CONF_MII1_RXD0_PUDEN rw — Pad Pullup / Pulldown Enable. [[br]]This is an active low signal [[br]]1 = Pullup / Pulldown disabled [[br]]0 = Pullup / Pulldown enabled
  [3:0] CONF_MII1_RXD0_MMODE rw — Pad Functional Signal Mux Select
0x944 CTRL_CONF_RMII1_REFCLK
  [30] CONF_RMII1_REFCLK_WUEVT ro — Wakeup Event [[br]]0 = No event [[br]]1 = Event occurred
  [29] CONF_RMII1_REFCLK_WUEN rw — Wakeup enable [[br]]0 = disable [[br]]1 = enable
  [28] CONF_RMII1_REFCLK_DSPULLTYPESELECT rw — DS0 mode Pull-Up/Down selection [[br]]0 = Offmode Pull-Down selected [[br]]1 = Offmode Pull-Up selected
  [27] CONF_RMII1_REFCLK_DSPULLUDEN rw — DS0 mode Pull-Up/Down enable. [[br]]This is an active low signal. [[br]]1 = Pullup / Pulldown disabled [[br]]0 = Pullup / Pulldown enabled
  [26] CONF_RMII1_REFCLK_DS0OUTVALUE rw — DS0 mode output value [[br]]0 = Set value at 0 [[br]]1 = Set value at 1
  [25] CONF_RMII1_REFCLK_DS0OUTEN rw — DS0 mode output enable This is an active low signal [[br]]0 = Output Enable [[br]]1 = Output Disable
  [24] CONF_RMII1_REFCLK_DS0EN rw — DS0 mode override control [[br]]0: IO state keeps its previous state when DS0 mode is active [[br]]1: IO state is forced to OFF mode value when DS0 mode is active
  [19] CONF_RMII1_REFCLK_SLEWCTRL rw — Select between Faster or Slower Slew rate [[br]]0 = fast [[br]]1 = slow
  [18] CONF_RMII1_REFCLK_RXACTIVE rw — Input Enable Value for the PAD [[br]]0 = receiver disabled [[br]]1 = receiver enabled
  [17] CONF_RMII1_REFCLK_PUTYPESEL rw — Pad Pullup / Pulldown Type Selection [[br]]0 = Pulldown selected [[br]]1 = Pullup selected
  [16] CONF_RMII1_REFCLK_PUDEN rw — Pad Pullup / Pulldown Enable. [[br]]This is an active low signal [[br]]1 = Pullup / Pulldown disabled [[br]]0 = Pullup / Pulldown enabled
  [3:0] CONF_RMII1_REFCLK_MMODE rw — Pad Functional Signal Mux Select
0x948 CTRL_CONF_MDIO_DATA
  [30] CONF_MDIO_DATA_WUEVT ro — Wakeup Event [[br]]0 = No event [[br]]1 = Event occurred
  [29] CONF_MDIO_DATA_WUEN rw — Wakeup enable [[br]]0 = disable [[br]]1 = enable
  [28] CONF_MDIO_DATA_DSPULLTYPESELECT rw — DS0 mode Pull-Up/Down selection [[br]]0 = Offmode Pull-Down selected [[br]]1 = Offmode Pull-Up selected
  [27] CONF_MDIO_DATA_DSPULLUDEN rw — DS0 mode Pull-Up/Down enable. [[br]]This is an active low signal. [[br]]1 = Pullup / Pulldown disabled [[br]]0 = Pullup / Pulldown enabled
  [26] CONF_MDIO_DATA_DS0OUTVALUE rw — DS0 mode output value [[br]]0 = Set value at 0 [[br]]1 = Set value at 1
  [25] CONF_MDIO_DATA_DS0OUTEN rw — DS0 mode output enable This is an active low signal [[br]]0 = Output Enable [[br]]1 = Output Disable
  [24] CONF_MDIO_DATA_DS0EN rw — DS0 mode override control [[br]]0: IO state keeps its previous state when DS0 mode is active [[br]]1: IO state is forced to OFF mode value when DS0 mode is active
  [19] CONF_MDIO_DATA_SLEWCTRL rw — Select between Faster or Slower Slew rate [[br]]0 = fast [[br]]1 = slow
  [18] CONF_MDIO_DATA_RXACTIVE rw — Input Enable Value for the PAD [[br]]0 = receiver disabled [[br]]1 = receiver enabled
  [17] CONF_MDIO_DATA_PUTYPESEL rw — Pad Pullup / Pulldown Type Selection [[br]]0 = Pulldown selected [[br]]1 = Pullup selected
  [16] CONF_MDIO_DATA_PUDEN rw — Pad Pullup / Pulldown Enable. [[br]]This is an active low signal [[br]]1 = Pullup / Pulldown disabled [[br]]0 = Pullup / Pulldown enabled
  [3:0] CONF_MDIO_DATA_MMODE rw — Pad Functional Signal Mux Select
